# RN831X_RN861X_MCU register map
File version: v0.0.1
CPU: RN831X_RN861X_MCU r1p0, little endian, MPU, no FPU
Registers are 32-bit, read-write, reset 0x0 unless marked. A register's access mark holds for its fields unless they carry their own. Offsets are from the block's base; [hi:lo] are bit positions; {n}, {i} and the like mark numbered series.

## LPUART_CORE0 — LPUART Module core0
Base 0x20020000
Same registers: LPUART_CORE1 0xA0020000
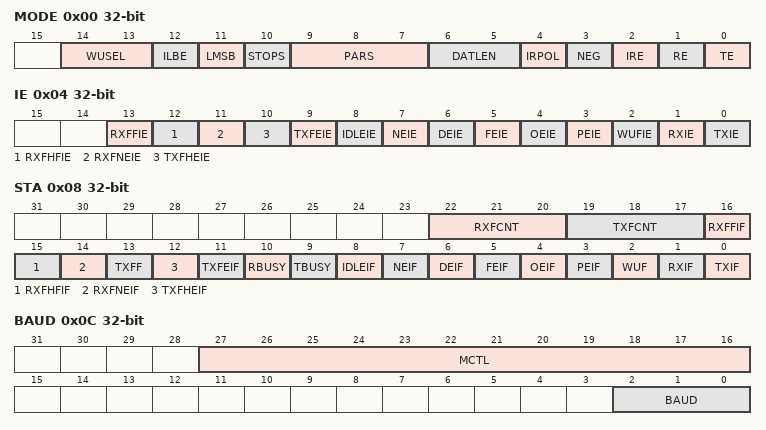
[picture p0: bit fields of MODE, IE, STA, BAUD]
0x00 MODE — Mode Configuration Register
  [14:13] WUSEL — Wakeup Event Configuration
    0=STARTBIT (Start bit detection); 1=RXFALLINGEDGE (RX falling edge detection); 2=RXCOMPLETE (Data reception complete); 3=FRAMEMATCH (Frame data match successful)
  [12] ILBE — Internal Loopback Enable
  [11] LMSB — LSB/MSB Transmission Order Select
  [10] STOPS — Stop Bit Width Select
    0=1 stop bit; 1=2 stop bits
  [9:7] PARS — Parity Selection
    0=NONE (No parity); 1=ODD (Odd parity); 2=EVEN (Even parity); 3=ZERO (Fixed to 0 parity); 4=ONE (Fixed to 1 parity); 5=USER_DEFINED (User-defined parity)
  [6:5] DATLEN — Data Length - excludes parity bit
    {v}={v+5}B ({v+5} bits data length) (v=0..3)
  [4] IRPOL — Transmit watermark level
    0=POSITIVE (Positive polarity (Idle level = High, Modulation = Low)); 1=NEGATIVE (Negative polarity (Idle level = Low, Modulation = High))
  [3] NEG — Clear TX channel and stop & clear transmission
    0=POSITIVE (Positive polarity (Idle level = High)); 1=NEGATIVE (Negative polarity (Idle level = Low))
  [2] IRE — Infrared Enable
  [1] RE — Receiver Enable
  [0] TE — Transmitter Enable
0x04 IE — Interrupt Enable Register
  [13] RXFFIE — RX FIFO Full Interrupt Enable
  [12] RXFHFIE — RX FIFO Half Full Interrupt Enable
  [11] RXFNEIE — RX FIFO Not Empty Interrupt Enable
  [10] TXFHEIE — TX FIFO Half Empty Interrupt Enable
  [9] TXFEIE — TX FIFO Empty Interrupt Enable
  [8] IDLEIE — Idle Frame Detected Interrupt Enable
  [7] NEIE — Start Bit Noise Detected Interrupt Enable
  [6] DEIE — Data Error Interrupt Enable
  [5] FEIE — Framing Error Interrupt Enable
  [4] OEIE — Overrun Error Interrupt Enable
  [3] PEIE — Parity Error Interrupt Enable
  [2] WUFIE — Wakeup from Sleep Interrupt Enable
  [1] RXIE — Receive Complete Interrupt Enable
  [0] TXIE — Transmit Complete Interrupt Enable
0x08 STA access per field — Status Register
  [22:20] RXFCNT ro — RX FIFO Data Count
  [19:17] TXFCNT ro — TX FIFO Data Count
  [16] RXFFIF rw write-1-clears — RX FIFO Full Flag
  [15] RXFHFIF rw write-1-clears — RX FIFO Half Full Flag
  [14] RXFNEIF rw write-1-clears — RX FIFO Not Empty Flag
  [13] TXFF rw write-1-clears — TX FIFO Full Flag
  [12] TXFHEIF rw write-1-clears — TX FIFO Half Empty Flag
  [11] TXFEIF rw write-1-clears — TX FIFO Empty Flag
  [10] RBUSY ro — Receiver Busy Flag
  [9] TBUSY ro — Transmitter Busy Flag
  [8] IDLEIF rw write-1-clears — Idle Frame Detected Flag
  [7] NEIF rw write-1-clears — Start Bit Noise Detected Flag
  [6] DEIF rw write-1-clears — Data Error Flag
  [5] FEIF rw write-1-clears — Framing Error Flag
  [4] OEIF rw write-1-clears — Overrun Error Flag
  [3] PEIF rw write-1-clears — Parity Error Flag
  [2] WUF rw write-1-clears — Wakeup Event Flag
  [1] RXIF rw write-1-clears — Receive Complete Flag
  [0] TXIF rw write-1-clears — Transmit Complete Flag
0x0C BAUD — Baud Rate Register
  [27:16] MCTL — Baud Rate Select
    0x4A5=Baud Rate is 9600bps, set MCTL; 0xF7D=Baud Rate is 4800bps, set MCTL; 0x6DB=Baud Rate is 2400bps, set MCTL; 0x407=Baud Rate is 1200bps, set MCTL; 127=Baud Rate is 600bps, set MCTL; 0x803=Baud Rate is 300bps, set MCTL
  [2:0] BAUD — Bit Width Modulation Control
    0=Baud Rate is 9600bps; 1=Baud Rate is 4800bps; 2=Baud Rate is 2400bps; 3=Baud Rate is 1200bps; 4=Baud Rate is 600bps; 5=Baud Rate is 300bps
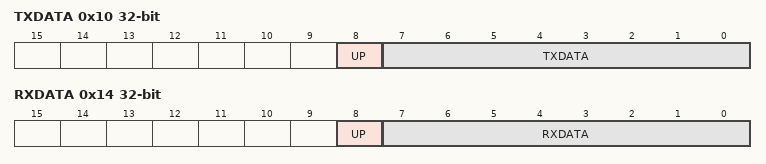
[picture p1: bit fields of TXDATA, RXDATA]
0x10 TXDATA — Transmit Data Buffer Register
  [8] UP — User Parity Bit
  [7:0] TXDATA — Transmit Data
0x14 RXDATA — Receive Data Buffer Register
  [8] UP — User Parity Bit
  [7:0] RXDATA — Receive Data
0x18 DMR access not given — Data Match Register
  [7:0] MDATA — Match Data. Compares with the first received frame of data. If a match is detected, it triggers the wakeup interrupt (used for wakeup from sleep mode).
